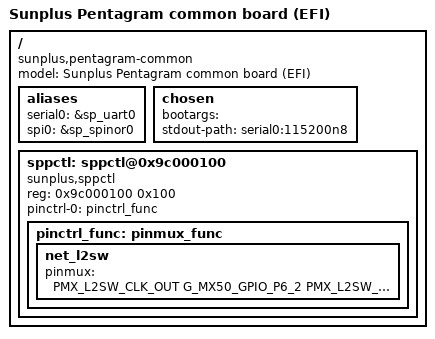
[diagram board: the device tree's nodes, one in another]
/*
 * Sunplus Pentagram board DTS
 *
 * SPDX-License-Identifier:	GPL-2.0+
 */
/dts-v1/;
#include "pentagram-sp70xx.dtsi"

/ {
	model = "Sunplus Pentagram common board (EFI)";
	compatible = "sunplus,pentagram-common", "sunplus,pentagram";

	aliases {
		serial0 = &sp_uart0;
		spi0 = &sp_spinor0;
	};

	chosen {
		bootargs = "";
		stdout-path = "serial0:115200n8";
	};

	sppctl: sppctl@0x9c000100 {
		compatible = "sunplus,sppctl";
		reg = <0x9c000100 0x100>;
		pinctrl-names = "default";
		pinctrl-0 = <&pinctrl_func>;

		pinctrl_func: pinmux_func {
			net_l2sw {

#if 0 // Ev board BPI: 0 for Demo board
				pinmux = <PMX_L2SW_CLK_OUT              G_MX47_GPIO_P5_7
					  PMX_L2SW_MAC_SMI_MDC          G_MX41_GPIO_P5_1
					  PMX_L2SW_LED_FLASH0           G_MX42_GPIO_P5_2
					  PMX_L2SW_LED_FLASH1           G_MX30_GPIO_P3_6
					  PMX_L2SW_LED_ON0              G_MX51_GPIO_P6_3
					  PMX_L2SW_LED_ON1              G_MX39_GPIO_P4_7
					  PMX_L2SW_MAC_SMI_MDIO         G_MX40_GPIO_P5_0
					  PMX_L2SW_P0_MAC_RMII_TXEN     G_MX50_GPIO_P6_2
					  PMX_L2SW_P0_MAC_RMII_TXD0     G_MX48_GPIO_P6_0
					  PMX_L2SW_P0_MAC_RMII_TXD1     G_MX49_GPIO_P6_1
					  PMX_L2SW_P0_MAC_RMII_CRSDV    G_MX44_GPIO_P5_4
					  PMX_L2SW_P0_MAC_RMII_RXD0     G_MX45_GPIO_P5_5
					  PMX_L2SW_P0_MAC_RMII_RXD1     G_MX46_GPIO_P5_6
					  PMX_L2SW_P0_MAC_RMII_RXER     G_MX43_GPIO_P5_3
					  PMX_L2SW_P1_MAC_RMII_TXEN     G_MX38_GPIO_P4_6
					  PMX_L2SW_P1_MAC_RMII_TXD0     G_MX36_GPIO_P4_4
					  PMX_L2SW_P1_MAC_RMII_TXD1     G_MX37_GPIO_P4_5
					  PMX_L2SW_P1_MAC_RMII_CRSDV    G_MX32_GPIO_P4_0
					  PMX_L2SW_P1_MAC_RMII_RXD0     G_MX33_GPIO_P4_1
					  PMX_L2SW_P1_MAC_RMII_RXD1     G_MX34_GPIO_P4_2
					  PMX_L2SW_P1_MAC_RMII_RXER     G_MX31_GPIO_P3_7
				>;
#else // Demo board
				pinmux = <PMX_L2SW_CLK_OUT              G_MX50_GPIO_P6_2
					  PMX_L2SW_MAC_SMI_MDC          G_MX44_GPIO_P5_4
					  PMX_L2SW_LED_FLASH0           G_MX54_GPIO_P6_6
					  PMX_L2SW_LED_ON0              G_MX45_GPIO_P5_5
					  PMX_L2SW_MAC_SMI_MDIO         G_MX43_GPIO_P5_3
					  PMX_L2SW_P0_MAC_RMII_TXEN     G_MX53_GPIO_P6_5
					  PMX_L2SW_P0_MAC_RMII_TXD0     G_MX51_GPIO_P6_3
					  PMX_L2SW_P0_MAC_RMII_TXD1     G_MX52_GPIO_P6_4
					  PMX_L2SW_P0_MAC_RMII_CRSDV    G_MX47_GPIO_P5_7
					  PMX_L2SW_P0_MAC_RMII_RXD0     G_MX48_GPIO_P6_0
					  PMX_L2SW_P0_MAC_RMII_RXD1     G_MX49_GPIO_P6_1
					  PMX_L2SW_P0_MAC_RMII_RXER     G_MX46_GPIO_P5_6
				>;
#endif
			};
		};
	};
};
